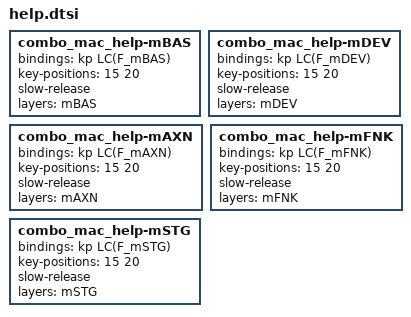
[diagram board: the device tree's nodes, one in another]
combo_mac_help-mBAS {
    bindings = <&kp LC(F_mBAS)>;
    key-positions = <15 20>;
    slow-release;
    layers = <mBAS>;
};

combo_mac_help-mDEV {
    bindings = <&kp LC(F_mDEV)>;
    key-positions = <15 20>;
    slow-release;
    layers = <mDEV>;
};

combo_mac_help-mAXN {
    bindings = <&kp LC(F_mAXN)>;
    key-positions = <15 20>;
    slow-release;
    layers = <mAXN>;
};

combo_mac_help-mFNK {
    bindings = <&kp LC(F_mFNK)>;
    key-positions = <15 20>;
    slow-release;
    layers = <mFNK>;
};

combo_mac_help-mSTG {
    bindings = <&kp LC(F_mSTG)>;
    key-positions = <15 20>;
    slow-release;
    layers = <mSTG>;
};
